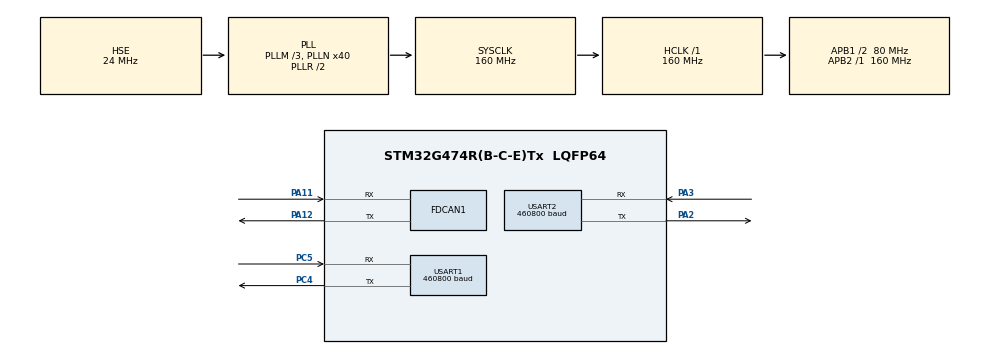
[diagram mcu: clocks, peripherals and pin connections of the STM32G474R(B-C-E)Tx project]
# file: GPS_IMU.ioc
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FDCAN1.CalculateBaudRateNominal=1000000
FDCAN1.CalculateTimeBitNominal=1000
FDCAN1.CalculateTimeQuantumNominal=25.0
FDCAN1.DataPrescaler=2
FDCAN1.DataTimeSeg1=5
FDCAN1.DataTimeSeg2=2
FDCAN1.FrameFormat=FDCAN_FRAME_FD_BRS
FDCAN1.Mode=FDCAN_MODE_NORMAL
FDCAN1.NominalPrescaler=2
FDCAN1.NominalSyncJumpWidth=2
FDCAN1.NominalTimeSeg1=31
FDCAN1.NominalTimeSeg2=8
FDCAN1.ProtocolException=DISABLE
FDCAN1.StdFiltersNbr=1
FREERTOS.Tasks01=defaultTask,24,128,StartDefaultTask,Default,NULL,Dynamic,NULL,NULL
Mcu.Family=STM32G4
Mcu.Name=STM32G474R(B-C-E)Tx
Mcu.Package=LQFP64
NVIC.PriorityGroup=NVIC_PRIORITYGROUP_4
NVIC.TIM6_DAC_IRQn=true\:15\:0\:false\:false\:true\:false\:false\:true\:true
NVIC.TimeBase=TIM6_DAC_IRQn
NVIC.TimeBaseIP=TIM6
NVIC.USART1_IRQn=true\:5\:0\:false\:false\:true\:true\:true\:true\:true
NVIC.USART2_IRQn=true\:5\:0\:false\:false\:true\:true\:true\:true\:true
PA11.Mode=FDCAN_Activate
PA11.Signal=FDCAN1_RX
PA12.Mode=FDCAN_Activate
PA12.Signal=FDCAN1_TX
PA13.Mode=Trace_Asynchronous_SW
PA13.Signal=SYS_JTMS-SWDIO
PA14.Mode=Trace_Asynchronous_SW
PA14.Signal=SYS_JTCK-SWCLK
PA2.Mode=Asynchronous
PA2.Signal=USART2_TX
PA3.Mode=Asynchronous
PA3.Signal=USART2_RX
PB3.Mode=Trace_Asynchronous_SW
PB3.Signal=SYS_JTDO-SWO
PC4.Mode=Asynchronous
PC4.Signal=USART1_TX
PC5.Mode=Asynchronous
PC5.Signal=USART1_RX
PF0-OSC_IN.Mode=HSE-External-Oscillator
PF0-OSC_IN.Signal=RCC_OSC_IN
PF1-OSC_OUT.Mode=HSE-External-Oscillator
PF1-OSC_OUT.Signal=RCC_OSC_OUT
ProjectManager.HeapSize=0x200
ProjectManager.StackSize=0x400
ProjectManager.TargetToolchain=STM32CubeIDE
RCC.ADC12Freq_Value=160000000
RCC.ADC345Freq_Value=160000000
RCC.AHBFreq_Value=160000000
RCC.APB1CLKDivider=RCC_HCLK_DIV2
RCC.APB1Freq_Value=80000000
RCC.APB1TimFreq_Value=160000000
RCC.APB2Freq_Value=160000000
RCC.APB2TimFreq_Value=160000000
RCC.CortexFreq_Value=160000000
RCC.EXTERNAL_CLOCK_VALUE=12288000
RCC.HCLKFreq_Value=160000000
RCC.HSE_VALUE=24000000
RCC.HSI48_VALUE=48000000
RCC.HSI_VALUE=16000000
RCC.LSE_VALUE=32768
RCC.PLLM=RCC_PLLM_DIV3
RCC.PLLN=40
RCC.PLLSourceVirtual=RCC_PLLSOURCE_HSE
RCC.SYSCLKFreq_VALUE=160000000
RCC.SYSCLKSource=RCC_SYSCLKSOURCE_PLLCLK
RCC.USBFreq_Value=160000000
RCC.VCOOutputFreq_Value=320000000
USART1.BaudRate=460800
USART1.SwapParam=ADVFEATURE_SWAP_DISABLE
USART1.VirtualMode-Asynchronous=VM_ASYNC
USART2.BaudRate=460800
USART2.VirtualMode-Asynchronous=VM_ASYNC
VP_FREERTOS_VS_CMSIS_V2.Mode=CMSIS_V2
VP_SYS_VS_DBSignals.Mode=DisableDeadBatterySignals
VP_SYS_VS_tim6.Mode=TIM6
board=custom

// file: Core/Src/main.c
/* USER CODE BEGIN Header */
/**
  ******************************************************************************
  * @file           : main.c
  * @brief          : Main program body
  ******************************************************************************
  * @attention
  *
  * Copyright (c) 2024 STMicroelectronics.
  * All rights reserved.
  *
  * This software is licensed under terms that can be found in the LICENSE file
  * in the root directory of this software component.
  * If no LICENSE file comes with this software, it is provided AS-IS.
  *
  ******************************************************************************
  */
/* USER CODE END Header */
#include "main.h"
#include "cmsis_os.h"
#include "fdcan.h"
#include "usart.h"
#include "gpio.h"

void SystemClock_Config(void);
void MX_FREERTOS_Init(void);

int main(void)
{

  /* MCU Configuration--------------------------------------------------------*/

  /* Reset of all peripherals, Initializes the Flash interface and the Systick. */
  HAL_Init();

  /* Configure the system clock */
  SystemClock_Config();

  /* Initialize all configured peripherals */
  MX_GPIO_Init();
  MX_FDCAN1_Init();
  MX_USART1_UART_Init();
  MX_USART2_UART_Init();
  /* USER CODE BEGIN 2 */
  // Wait for GPS to start
//  HAL_Delay(5000);
  // LOG_BESTPOS command

  /* USER CODE END 2 */

  /* Init scheduler */
  osKernelInitialize();

  /* Call init function for freertos objects (in cmsis_os2.c) */
  MX_FREERTOS_Init();

  /* Start scheduler */
  osKernelStart();

  /* We should never get here as control is now taken by the scheduler */

  /* Infinite loop */
  while (1)
  {

  }
}

void SystemClock_Config(void)
{
  RCC_OscInitTypeDef RCC_OscInitStruct = {0};
  RCC_ClkInitTypeDef RCC_ClkInitStruct = {0};

  /** Configure the main internal regulator output voltage
  */
  HAL_PWREx_ControlVoltageScaling(PWR_REGULATOR_VOLTAGE_SCALE1_BOOST);

  /** Initializes the RCC Oscillators according to the specified parameters
  * in the RCC_OscInitTypeDef structure.
  */
  RCC_OscInitStruct.OscillatorType = RCC_OSCILLATORTYPE_HSE;
  RCC_OscInitStruct.HSEState = RCC_HSE_ON;
  RCC_OscInitStruct.PLL.PLLState = RCC_PLL_ON;
  RCC_OscInitStruct.PLL.PLLSource = RCC_PLLSOURCE_HSE;
  RCC_OscInitStruct.PLL.PLLM = RCC_PLLM_DIV3;
  RCC_OscInitStruct.PLL.PLLN = 40;
  RCC_OscInitStruct.PLL.PLLP = RCC_PLLP_DIV2;
  RCC_OscInitStruct.PLL.PLLQ = RCC_PLLQ_DIV2;
  RCC_OscInitStruct.PLL.PLLR = RCC_PLLR_DIV2;
  if (HAL_RCC_OscConfig(&RCC_OscInitStruct) != HAL_OK)
  {
    Error_Handler();
  }

  /** Initializes the CPU, AHB and APB buses clocks
  */
  RCC_ClkInitStruct.ClockType = RCC_CLOCKTYPE_HCLK|RCC_CLOCKTYPE_SYSCLK
                              |RCC_CLOCKTYPE_PCLK1|RCC_CLOCKTYPE_PCLK2;
  RCC_ClkInitStruct.SYSCLKSource = RCC_SYSCLKSOURCE_PLLCLK;
  RCC_ClkInitStruct.AHBCLKDivider = RCC_SYSCLK_DIV1;
  RCC_ClkInitStruct.APB1CLKDivider = RCC_HCLK_DIV2;
  RCC_ClkInitStruct.APB2CLKDivider = RCC_HCLK_DIV1;

  if (HAL_RCC_ClockConfig(&RCC_ClkInitStruct, FLASH_LATENCY_4) != HAL_OK)
  {
    Error_Handler();
  }
}

void HAL_TIM_PeriodElapsedCallback(TIM_HandleTypeDef *htim)
{
  if (htim->Instance == TIM6) {
    HAL_IncTick();
  }
}

void Error_Handler(void)
{
  __disable_irq();
  while (1)
  {
  }
}

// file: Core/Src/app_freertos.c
/* USER CODE BEGIN Header */
/**
  ******************************************************************************
  * File Name          : app_freertos.c
  * Description        : Code for freertos applications
  ******************************************************************************
  * @attention
  *
  * Copyright (c) 2024 STMicroelectronics.
  * All rights reserved.
  *
  * This software is licensed under terms that can be found in the LICENSE file
  * in the root directory of this software component.
  * If no LICENSE file comes with this software, it is provided AS-IS.
  *
  ******************************************************************************
  */
/* USER CODE END Header */

#include "FreeRTOS.h"
#include "task.h"
#include "main.h"
#include "cmsis_os.h"

/* USER CODE BEGIN Includes */
#include "app.h"
/* USER CODE END Includes */

/* Definitions for defaultTask */
osThreadId_t defaultTaskHandle;
const osThreadAttr_t defaultTask_attributes = {
  .name = "defaultTask",
  .priority = (osPriority_t) osPriorityNormal,
  .stack_size = 128 * 4
};

void StartDefaultTask(void *argument);

void MX_FREERTOS_Init(void); /* (MISRA C 2004 rule 8.1) */

void MX_FREERTOS_Init(void) {

  /* USER CODE BEGIN RTOS_QUEUES */
    RTOS_Init();
  /* USER CODE END RTOS_QUEUES */

  /* Create the thread(s) */
  /* creation of defaultTask */
  defaultTaskHandle = osThreadNew(StartDefaultTask, NULL, &defaultTask_attributes);

}

void StartDefaultTask(void *argument)
{
  for(;;)
  {
    osDelay(1);
  }
}
